# STM32G0C1xx register map
File version: 1.0
Registers are 32-bit, read-write, reset 0x0 unless marked. A register's access mark holds for its fields unless they carry their own. Offsets are from the block's base; [hi:lo] are bit positions; {n}, {i} and the like mark numbered series.

## RCC — Reset and Clock Control
Base 0x40021000
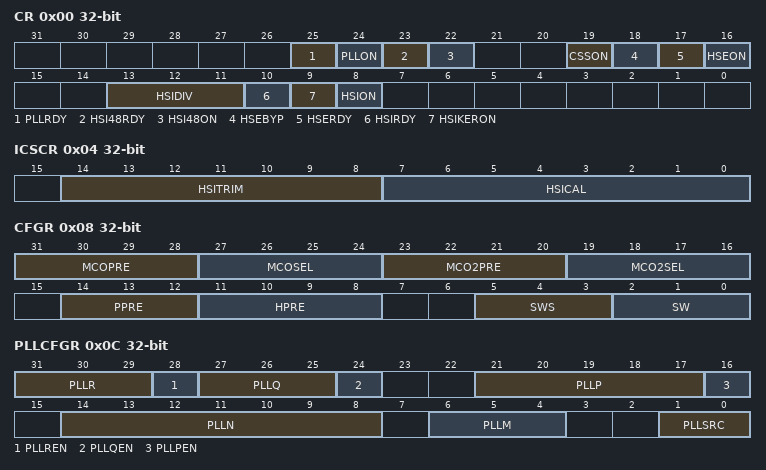
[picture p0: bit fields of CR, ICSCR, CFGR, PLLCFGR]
0x00 CR — RCC Clock Sources Control Register
  [25] PLLRDY — System PLL clock ready
  [24] PLLON — System PLL clock enable
  [23] HSI48RDY — RC48 clock ready
  [22] HSI48ON — RC48 clock enable
  [19] CSSON — HSE Clock Security System enable
  [18] HSEBYP — External High Speed clock Bypass
  [17] HSERDY — External High Speed clock ready
  [16] HSEON — External High Speed clock enable
  [13:11] HSIDIV — HSIDIV[13:11] Internal High Speed clock division factor
    0=DIV_1 (HSI not divided); 1=DIV_2 (HSI divided by 2); 2=DIV_4 (HSI divided by 4); 3=DIV_8 (HSI divided by 8); 4=DIV_16 (HSI divided by 16); 5=DIV_32 (HSI divided by 32); 6=DIV_64 (HSI divided by 64); 7=DIV_128 (HSI divided by 128)
  [10] HSIRDY — Internal High Speed clock ready flag
  [9] HSIKERON — Internal High Speed clock enable for some IPs Kernel
  [8] HSION — Internal High Speed clock enable
0x04 ICSCR — RCC Internal Clock Sources Calibration Register
  [14:8] HSITRIM — HSITRIM[14:8] bits
  [7:0] HSICAL — HSICAL[7:0] bits
0x08 CFGR — RCC Regulated Domain Clocks Configuration Register
  [31:28] MCOPRE — MCO prescaler [2:0]
  [27:24] MCOSEL — MCOSEL [2:0] bits (Clock output selection)
  [23:20] MCO2PRE — MCO2 prescaler [3:0]
  [19:16] MCO2SEL — MCO2SEL [3:0] bits (Clock output selection)
  [14:12] PPRE — PRE1[2:0] bits (APB prescaler)
    0=DIV_1 (HCLK not divided); 4=DIV_2 (HCLK divided by 2); 5=DIV_4 (HCLK divided by 4); 6=DIV_8 (HCLK divided by 8); 7=DIV_16 (HCLK divided by 16)
  [11:8] HPRE — HPRE[3:0] bits (AHB prescaler)
    0=DIV_1 (SYSCLK not divided); 8=DIV_2 (SYSCLK divided by 2); 9=DIV_4 (SYSCLK divided by 4); 10=DIV_8 (SYSCLK divided by 8); 11=DIV_16 (SYSCLK divided by 16); 12=DIV_64 (SYSCLK divided by 64); 13=DIV_128 (SYSCLK divided by 128); 14=DIV_256 (SYSCLK divided by 256); 15=DIV_512 (SYSCLK divided by 512)
  [5:3] SWS — SWS[2:0] bits (System Clock Switch Status)
    0=HSI (HSI used as system clock); 1=HSE (HSE used as system clock); 2=PLL (PLL used as system clock); 3=LSI (LSI used as system clock); 4=LSE (LSE used as system clock)
  [2:0] SW — SW[2:0] bits (System clock Switch)
    0=HSI (HSI selection as system clock); 1=HSE (HSE selection as system clock); 2=PLL (PLL selection as system clock); 3=LSI (LSI selection used as system clock); 4=LSE (LSE selection used as system clock)
0x0C PLLCFGR — RCC System PLL configuration Register
  [31:29] PLLR
    {v}=DIV_{v+1} (Main PLL division factor for PLLCLK (system clock) by {v+1}) (v=1..7)
  [28] PLLREN
  [27:25] PLLQ
    {v}=DIV_{v+1} (Main PLL division factor for PLLQ output by {v+1}) (v=1..7)
  [24] PLLQEN
  [21:17] PLLP
    {v}=DIV_{v+1} (Main PLL division factor for PLLP output by {v+1}) (v=1..31)
  [16] PLLPEN
  [14:8] PLLN
  [6:4] PLLM
    {v}=DIV_{v+1} (PLL division factor by {v+1}) (v=0..7)
  [1:0] PLLSRC
    2=HSI (HSI16 clock selected as PLL entry clock source); 3=HSE (HSE clock selected as PLL entry clock source); 0=NONE (No clock)
0x14 CRRCR — RCC Clock Configuration Register
  [8:0] HSI48CAL — RC48CAL[8:0] bits
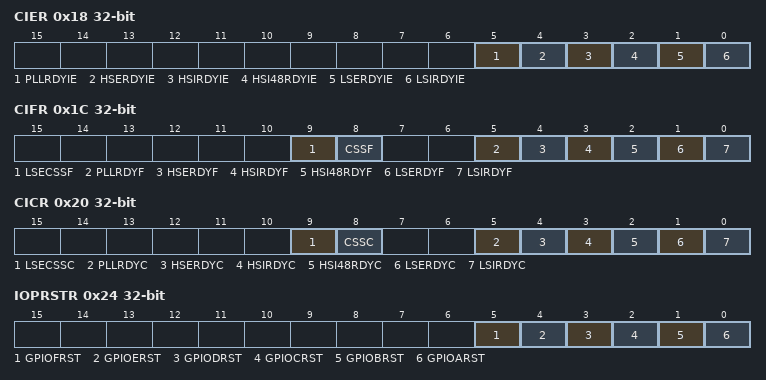
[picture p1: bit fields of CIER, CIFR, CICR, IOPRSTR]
0x18 CIER — RCC Clock Interrupt Enable Register
  [5] PLLRDYIE, [4] HSERDYIE, [3] HSIRDYIE, [2] HSI48RDYIE, [1] LSERDYIE, [0] LSIRDYIE
0x1C CIFR — RCC Clock Interrupt Flag Register
  [9] LSECSSF, [8] CSSF, [5] PLLRDYF, [4] HSERDYF, [3] HSIRDYF, [2] HSI48RDYF, [1] LSERDYF, [0] LSIRDYF
0x20 CICR — RCC Clock Interrupt Clear Register
  [9] LSECSSC, [8] CSSC, [5] PLLRDYC, [4] HSERDYC, [3] HSIRDYC, [2] HSI48RDYC, [1] LSERDYC, [0] LSIRDYC
0x24 IOPRSTR — RCC IO port reset register
  [5] GPIOFRST, [4] GPIOERST, [3] GPIODRST, [2] GPIOCRST, [1] GPIOBRST, [0] GPIOARST
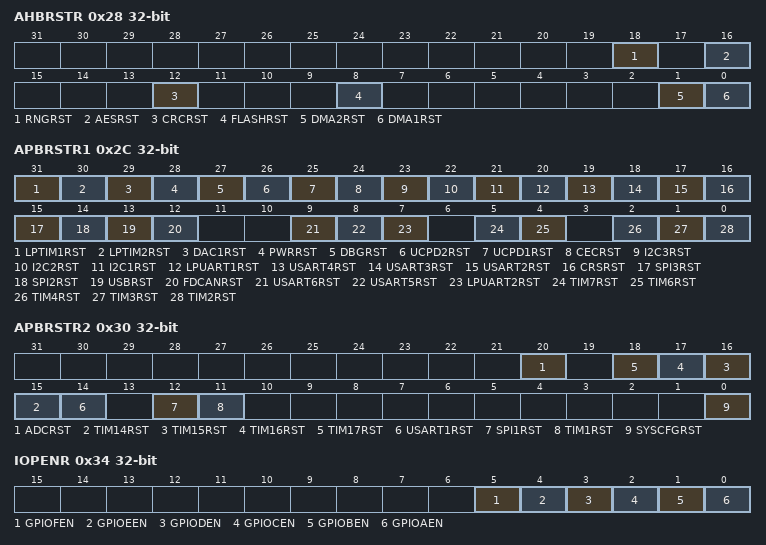
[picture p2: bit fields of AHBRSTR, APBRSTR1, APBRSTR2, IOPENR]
0x28 AHBRSTR — RCC AHB peripherals reset register
  [18] RNGRST, [16] AESRST, [12] CRCRST, [8] FLASHRST, [1] DMA2RST, [0] DMA1RST
0x2C APBRSTR1 — RCC APB peripherals reset register 1
  [31] LPTIM1RST, [30] LPTIM2RST, [29] DAC1RST, [28] PWRRST, [27] DBGRST, [26] UCPD2RST, [25] UCPD1RST, [24] CECRST, [23] I2C3RST, [22] I2C2RST, [21] I2C1RST, [20] LPUART1RST, [19] USART4RST, [18] USART3RST, [17] USART2RST, [16] CRSRST, [15] SPI3RST, [14] SPI2RST, [13] USBRST, [12] FDCANRST, [9] USART6RST, [8] USART5RST, [7] LPUART2RST, [5] TIM7RST, [4] TIM6RST, [2] TIM4RST, [1] TIM3RST, [0] TIM2RST
0x30 APBRSTR2 — RCC APB peripherals reset register 2
  [20] ADCRST, [n+1] TIM{n}RST (n=14..17), [14] USART1RST, [12] SPI1RST, [11] TIM1RST, [0] SYSCFGRST
0x34 IOPENR — RCC IO port enable register
  [5] GPIOFEN, [4] GPIOEEN, [3] GPIODEN, [2] GPIOCEN, [1] GPIOBEN, [0] GPIOAEN
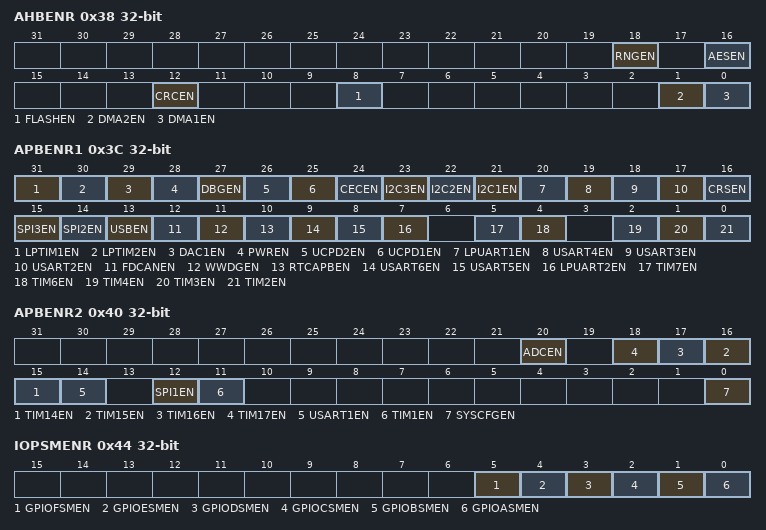
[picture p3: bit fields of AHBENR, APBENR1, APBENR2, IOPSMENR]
0x38 AHBENR — RCC AHB peripherals clock enable register
  [18] RNGEN, [16] AESEN, [12] CRCEN, [8] FLASHEN, [1] DMA2EN, [0] DMA1EN
0x3C APBENR1 — RCC APB peripherals clock enable register1
  [31] LPTIM1EN, [30] LPTIM2EN, [29] DAC1EN, [28] PWREN, [27] DBGEN, [26] UCPD2EN, [25] UCPD1EN, [24] CECEN, [23] I2C3EN, [22] I2C2EN, [21] I2C1EN, [20] LPUART1EN, [19] USART4EN, [18] USART3EN, [17] USART2EN, [16] CRSEN, [15] SPI3EN, [14] SPI2EN, [13] USBEN, [12] FDCANEN, [11] WWDGEN, [10] RTCAPBEN, [9] USART6EN, [8] USART5EN, [7] LPUART2EN, [5] TIM7EN, [4] TIM6EN, [2] TIM4EN, [1] TIM3EN, [0] TIM2EN
0x40 APBENR2 — RCC APB peripherals clock enable register2
  [20] ADCEN, [n+1] TIM{n}EN (n=14..17), [14] USART1EN, [12] SPI1EN, [11] TIM1EN, [0] SYSCFGEN
0x44 IOPSMENR — RCC IO port clocks enable in sleep mode register
  [5] GPIOFSMEN, [4] GPIOESMEN, [3] GPIODSMEN, [2] GPIOCSMEN, [1] GPIOBSMEN, [0] GPIOASMEN
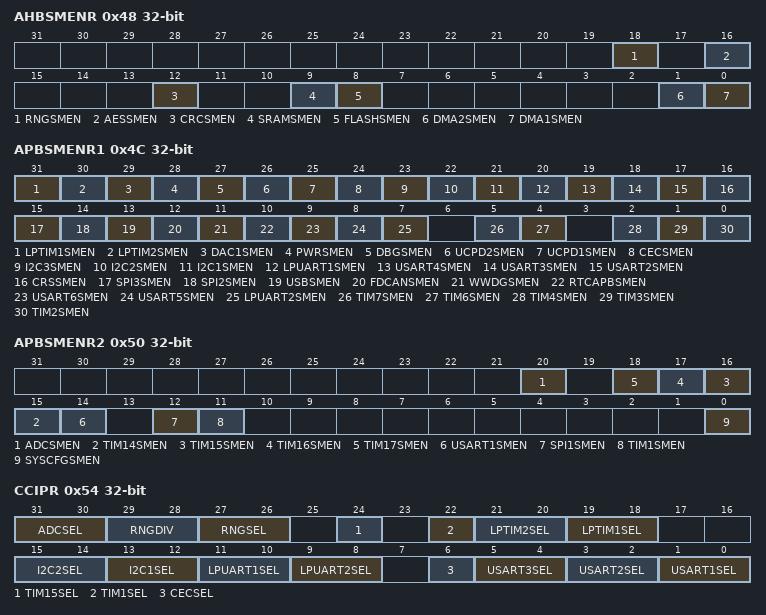
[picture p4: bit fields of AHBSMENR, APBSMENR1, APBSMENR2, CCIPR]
0x48 AHBSMENR — RCC AHB peripheral clocks enable in sleep mode register
  [18] RNGSMEN, [16] AESSMEN, [12] CRCSMEN, [9] SRAMSMEN, [8] FLASHSMEN, [1] DMA2SMEN, [0] DMA1SMEN
0x4C APBSMENR1 — RCC APB peripheral clocks enable in sleep mode register1
  [31] LPTIM1SMEN, [30] LPTIM2SMEN, [29] DAC1SMEN, [28] PWRSMEN, [27] DBGSMEN, [26] UCPD2SMEN, [25] UCPD1SMEN, [24] CECSMEN, [23] I2C3SMEN, [22] I2C2SMEN, [21] I2C1SMEN, [20] LPUART1SMEN, [19] USART4SMEN, [18] USART3SMEN, [17] USART2SMEN, [16] CRSSMEN, [15] SPI3SMEN, [14] SPI2SMEN, [13] USBSMEN, [12] FDCANSMEN, [11] WWDGSMEN, [10] RTCAPBSMEN, [9] USART6SMEN, [8] USART5SMEN, [7] LPUART2SMEN, [5] TIM7SMEN, [4] TIM6SMEN, [2] TIM4SMEN, [1] TIM3SMEN, [0] TIM2SMEN
0x50 APBSMENR2 — RCC APB peripheral clocks enable in sleep mode register2
  [20] ADCSMEN, [n+1] TIM{n}SMEN (n=14..17), [14] USART1SMEN, [12] SPI1SMEN, [11] TIM1SMEN, [0] SYSCFGSMEN
0x54 CCIPR — RCC Peripherals Independent Clocks Configuration Register
  [31:30] ADCSEL
    1=PLL (PLL used as ADC clock); 0=SYSCLK (SYSCLK used as ADC clock); 2=HSI (HSI used as ADC clock)
  [29:28] RNGDIV
    0=DIV1 (RNG clock not divided); 1=DIV2 (RNG clock divided by 2); 2=DIV4 (RNG clock divided by 4); 3=DIV8 (RNG clock divided by 8)
  [27:26] RNGSEL
    0=NONE (No clock used as RNG clock); 1=HSI_DIV8 (HSI oscillator clock divided by 8 used as RNG clock, available on cut2.0); 2=SYSCLK (SYSCLK divided by 1 used as RNG clock); 3=PLL (PLL used as RNG clock)
  [24] TIM15SEL
  [22] TIM1SEL
  [21:20] LPTIM2SEL
  [19:18] LPTIM1SEL
  [15:14] I2C2SEL
  [13:12] I2C1SEL
  [11:10] LPUART1SEL
  [9:8] LPUART2SEL
  [6] CECSEL
    0=HSI_DIV488 (HSI oscillator clock divided by 488 used as CEC clock); 1=LSE (LSE oscillator clock used as CEC clock)
  [5:4] USART3SEL
  [3:2] USART2SEL
  [1:0] USART1SEL
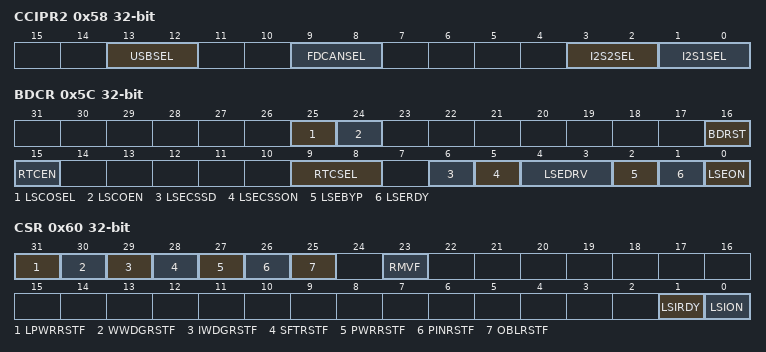
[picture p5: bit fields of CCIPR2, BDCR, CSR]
0x58 CCIPR2 — RCC Peripherals Independent Clocks Configuration Register2
  [13:12] USBSEL
    0=HSI48 (HSI48 clock used as USB clock source); 1=HSE (PLL clock used as USB clock source); 2=PLL (PLL clock used as USB clock source)
  [9:8] FDCANSEL
    2=HSE (HSE oscillator clock used as FDCAN clock); 0=PCLK1 (PCLK1 oscillator clock used as FDCAN clock); 1=PLL (PLL "Q" oscillator clock used as FDCAN clock)
  [3:2] I2S2SEL
  [1:0] I2S1SEL
0x5C BDCR — RCC Backup Domain Control Register
  [25] LSCOSEL
    0=LSI (LSI selection for low speed clock); 1=LSE (LSE selection for low speed clock)
  [24] LSCOEN
  [16] BDRST
  [15] RTCEN
  [9:8] RTCSEL
    0=NONE (No clock used as RTC clock); 1=LSE (LSE oscillator clock used as RTC clock); 2=LSI (LSI oscillator clock used as RTC clock); 3=HSE_DIV32 (HSE oscillator clock divided by 32 used as RTC clock)
  [6] LSECSSD
  [5] LSECSSON
  [4:3] LSEDRV
    0=LOW (Xtal mode lower driving capability); 1=MEDIUMLOW (Xtal mode medium low driving capability); 2=MEDIUMHIGH (Xtal mode medium high driving capability); 3=HIGH (Xtal mode higher driving capability)
  [2] LSEBYP
  [1] LSERDY
  [0] LSEON
0x60 CSR — RCC Unregulated Domain Clock Control and Status Register
  [31] LPWRRSTF, [30] WWDGRSTF, [29] IWDGRSTF, [28] SFTRSTF, [27] PWRRSTF, [26] PINRSTF, [25] OBLRSTF, [23] RMVF, [1] LSIRDY, [0] LSION
